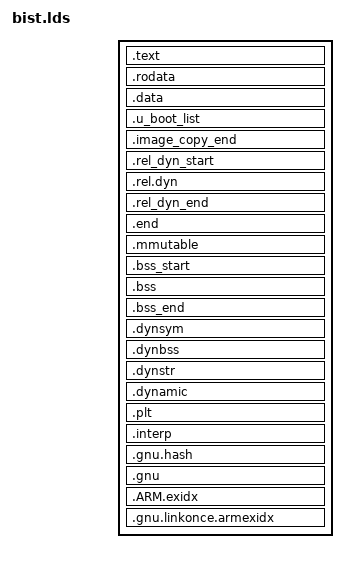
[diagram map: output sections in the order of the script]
/*
 * Copyright (c) 2004-2008 Texas Instruments
 *
 * (C) Copyright 2002
 * Gary Jennejohn, DENX Software Engineering, <garyj@denx.de>
 *
 * SPDX-License-Identifier:	GPL-2.0+
 */

OUTPUT_FORMAT("elf32-littlearm", "elf32-littlearm", "elf32-littlearm")
OUTPUT_ARCH(arm)
ENTRY(_start)
SECTIONS
{
	. = 0x00000000;

	. = ALIGN(4);
	.text :
	{
		*(.__image_copy_start)
		CPUDIR/start.o (.text*)
		*(.text*)
		*(.low_power_code)
		*(.__low_power_code_start)
		*(.low_power_code_suspend_resume)
		*(.__low_power_code_end)
	}

	. = ALIGN(4);
	.rodata : { *(SORT_BY_ALIGNMENT(SORT_BY_NAME(.rodata*))) }

	. = ALIGN(4);
	.data : {
		*(.data*)
		*(.low_power_data)
	}

	. = ALIGN(4);

	. = .;

	. = ALIGN(4);
	.u_boot_list : {
		KEEP(*(SORT(.u_boot_list*)));
	}
/*
	. = ALIGN(4);

	_low_power_code_start = .;
	.low_power_code (0x920000) : AT (_low_power_code_start)
	{
		*(.low_power_code)
		drivers/misc/fsl_mx6sl_lpm/suspend_resume.o (.low_power_code_suspend_resume)
	}
	
	_low_power_code_size = SIZEOF(.low_power_code);	

	.low_power_data (0x920000 + _low_power_code_size) : AT (_low_power_code_start + _low_power_code_size)
	{
		*(.low_power_data)
	}
	
	_low_power_data_size = SIZEOF(.low_power_data);
	_low_power_size = _low_power_code_size + _low_power_data_size;

	_low_power_copy_end = .;
*/
	. = ALIGN(4);

	.image_copy_end :
	{
		*(.__image_copy_end)
	}

	.rel_dyn_start :
	{
		*(.__rel_dyn_start)
	}

	.rel.dyn : {
		*(.rel*)
	}

	.rel_dyn_end :
	{
		*(.__rel_dyn_end)
	}

	.end :
	{
		*(.__end)
	}

	_image_binary_end = .;

	/*
	 * Deprecated: this MMU section is used by pxa at present but
	 * should not be used by new boards/CPUs.
	 */
	. = ALIGN(4096);
	.mmutable : {
		*(.mmutable)
	}

/*
 * Compiler-generated __bss_start and __bss_end, see arch/arm/lib/bss.c
 * __bss_base and __bss_limit are for linker only (overlay ordering)
 */

	.bss_start : {
		KEEP(*(.__bss_start));
		__bss_base = .;
	}

	.bss __bss_base : {
		*(.bss*)
		 . = ALIGN(4);
		 __bss_limit = .;
	}

	.bss_end __bss_limit : {
		KEEP(*(.__bss_end));
	}

	.dynsym _image_binary_end : { *(.dynsym) }
	.dynbss : { *(.dynbss) }
	.dynstr : { *(.dynstr*) }
	.dynamic : { *(.dynamic*) }
	.plt : { *(.plt*) }
	.interp : { *(.interp*) }
	.gnu.hash : { *(.gnu.hash) }
	.gnu : { *(.gnu*) }
	.ARM.exidx : { *(.ARM.exidx*) }
	.gnu.linkonce.armexidx : { *(.gnu.linkonce.armexidx.*) }

}
